# STM32H7B3x register map
File version: 2.2
CPU: CM7 r0p1, little endian, MPU, FPU, 4 interrupt priority bits
Registers are 32-bit, read-write, reset 0x0 unless marked. A register's access mark holds for its fields unless they carry their own. Offsets are from the block's base; [hi:lo] are bit positions; {n}, {i} and the like mark numbered series; 'fields as' and 'values as' point back to an identical list.

## RCC (part 2 of 3) — Reset and clock control
Base 0x58024400
0x44 PLL3FRACR
  [15:3] FRACN3 — fractional part of the multiplication factor for PLL3 VCO Set and reset by software to control the fractional part of the multiplication factor of the VCO. These bits can be written at any time, allowing dynamic fine-tuning of the PLL3 VCO. The software must set correctly these bits to insure that the VCO output frequency is between its valid frequency range, that is: 128 to 560Â MHz if PLL3VCOSEL = 0 150 to 420Â MHz if PLL3VCOSEL = 1 VCO output frequency = Fref3_ck x (DIVN3 + (FRACN3 / 213)), with DIVN3 between 8 and 420 FRACN3 can be between 0 and 213 - 1 The input frequency Fref3_ck must be between 1 and 16 MHz. In order to change the FRACN value on-the-fly even if the PLL is enabled, the application must proceed as follows: Set the bit PLL1FRACEN to 0. Write the new fractional value into FRACN1. Set the bit PLL1FRACEN to 1.
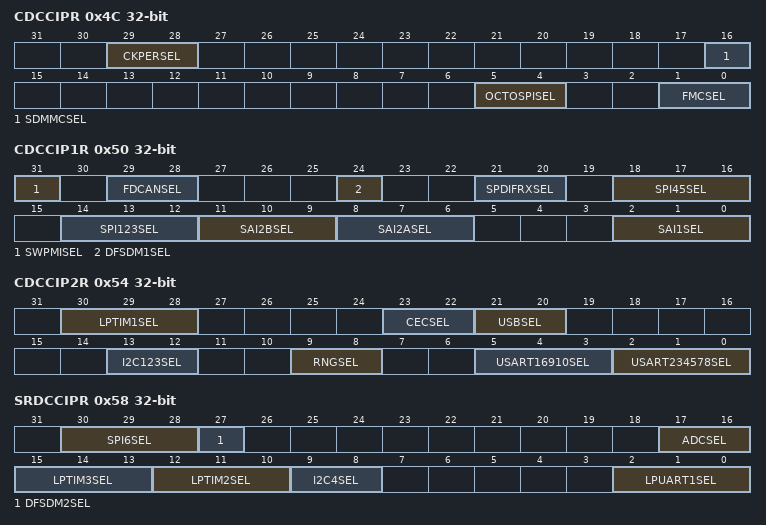
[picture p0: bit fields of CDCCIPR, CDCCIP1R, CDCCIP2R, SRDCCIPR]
0x4C CDCCIPR — RCC CPU domain kernel clock configuration register
  [29:28] CKPERSEL — per_ck clock source selection
    0=HSI (HSI selected as peripheral clock); 1=CSI (CSI selected as peripheral clock); 2=HSE (HSE selected as peripheral clock)
  [16] SDMMCSEL — SDMMC kernel clock source selection
    0=PLL1_Q (pll1_q selected as peripheral clock); 1=PLL2_R (pll2_r selected as peripheral clock)
  [5:4] OCTOSPISEL — OCTOSPI kernel clock source selection
    0=RCC_HCLK3 (rcc_hclk3 selected as peripheral clock); 1=PLL1_Q (pll1_q selected as peripheral clock); 2=PLL2_R (pll2_r selected as peripheral clock); 3=PER (PER selected as peripheral clock)
  [1:0] FMCSEL — FMC kernel clock source selection
    values as OCTOSPISEL
0x50 CDCCIP1R — RCC CPU domain kernel clock configuration register
  [31] SWPMISEL — SWPMI kernel clock source selection Set and reset by software.
    0=PCLK (pclk selected as peripheral clock); 1=HSI_KER (hsi_ker selected as peripheral clock)
  [29:28] FDCANSEL — FDCAN kernel clock source selection Set and reset by software.
    0=HSE (HSE selected as peripheral clock); 1=PLL1_Q (pll1_q selected as peripheral clock); 2=PLL2_Q (pll2_q selected as peripheral clock)
  [24] DFSDM1SEL — DFSDM1 kernel clock Clk source selection Set and reset by software. Note: the DFSDM1 Aclk clock source selection is done by SAI1SEL (see ).
    0=RCC_PCLK2 (rcc_pclk2 selected as peripheral clock); 1=SYS (System clock selected as peripheral clock)
  [21:20] SPDIFRXSEL — SPDIFRX kernel clock source selection
    0=PLL1_Q (pll1_q selected as peripheral clock); 1=PLL2_R (pll2_r selected as peripheral clock); 2=PLL3_R (pll3_r selected as peripheral clock); 3=HSI_KER (hsi_ker selected as peripheral clock)
  [18:16] SPI45SEL — SPI4 and 5 kernel clock source selection Set and reset by software. others: reserved, the kernel clock is disabled
    0=APB (APB clock selected as peripheral clock); 1=PLL2_Q (pll2_q selected as peripheral clock); 2=PLL3_Q (pll3_q selected as peripheral clock); 3=HSI_KER (hsi_ker selected as peripheral clock); 4=CSI_KER (csi_ker selected as peripheral clock); 5=HSE (HSE selected as peripheral clock)
  [14:12] SPI123SEL — SPI/I2S1,2 and 3 kernel clock source selection Set and reset by software. If the selected clock is the external clock and this clock is stopped, it is not be possible to switch to another clock. Refer to for additional information. others: reserved, the kernel clock is disabled Note: I2S_CKIN is an external clock taken from a pin.
    0=PLL1_Q (pll1_q selected as peripheral clock); 1=PLL2_P (pll2_p selected as peripheral clock); 2=PLL3_P (pll3_p selected as peripheral clock); 3=I2S_CKIN (I2S_CKIN selected as peripheral clock); 4=PER (PER selected as peripheral clock)
  [11:9] SAI2BSEL — SAI2 kernel clock B source selection Set and reset by software. If the selected clock is the external clock and this clock is stopped, it is not be possible to switch to another clock. Refer to for additional information. others: reserved, the kernel clock is disabled Note: I2S_CKIN is an external clock taken from a pin. spdifrx_symb_ck is the symbol clock generated by the spdifrx (see ).
    0=PLL1_Q (pll1_q selected as peripheral clock); 1=PLL2_P (pll2_p selected as peripheral clock); 2=PLL3_P (pll3_p selected as peripheral clock); 3=I2S_CKIN (i2s_ckin selected as peripheral clock); 4=PER (PER selected as peripheral clock)
  [8:6] SAI2ASEL — SAI2 kernel clock source A selection Set and reset by software. If the selected clock is the external clock and this clock is stopped, it is not be possible to switch to another clock. Refer to for additional information. others: reserved, the kernel clock is disabled Note: I2S_CKIN is an external clock taken from a pin. spdifrx_symb_ck is the symbol clock generated by the SPDIFRX (see ).
    values as SAI2BSEL
  [2:0] SAI1SEL — SAI1 and DFSDM1 kernel Aclk clock source selection Set and reset by software. If the selected clock is the external clock and this clock is stopped, it isnot be possible to switch to another clock. Refer to for additional information. Note: DFSDM1 clock source selection is done by DFSDM1SEL. others: reserved, the kernel clock is disabled Note: I2S_CKIN is an external clock taken from a pin.
    values as SPI123SEL
0x54 CDCCIP2R — RCC CPU domain kernel clock configuration register
  [30:28] LPTIM1SEL — LPTIM1 kernel clock source selection Set and reset by software. others: reserved, the kernel clock is disabled
    0=RCC_PCLK1 (rcc_pclk1 selected as peripheral clock); 1=PLL2_P (pll2_p selected as peripheral clock); 2=PLL3_R (pll3_r selected as peripheral clock); 3=LSE (LSE selected as peripheral clock); 4=LSI (LSI selected as peripheral clock); 5=PER (PER selected as peripheral clock)
  [23:22] CECSEL — HDMI-CEC kernel clock source selection Set and reset by software.
    0=LSE (LSE selected as peripheral clock); 1=LSI (LSI selected as peripheral clock); 2=CSI_KER (csi_ker selected as peripheral clock)
  [21:20] USBSEL — USBOTG 1 and 2 kernel clock source selection Set and reset by software.
    0=DISABLE (Disable the kernel clock); 1=PLL1_Q (pll1_q selected as peripheral clock); 2=PLL3_Q (pll3_q selected as peripheral clock); 3=HSI48 (HSI48 selected as peripheral clock)
  [13:12] I2C123SEL — I2C1,2,3 kernel clock source selection Set and reset by software.
    0=RCC_PCLK1 (rcc_pclk1 selected as peripheral clock); 1=PLL3_R (pll3_r selected as peripheral clock); 2=HSI_KER (hsi_ker selected as peripheral clock); 3=CSI_KER (csi_ker selected as peripheral clock)
  [9:8] RNGSEL — RNG kernel clock source selection Set and reset by software.
    0=HSI48 (HSI48 selected as peripheral clock); 1=PLL1_Q (pll1_q selected as peripheral clock); 2=LSE (LSE selected as peripheral clock); 3=LSI (LSI selected as peripheral clock)
  [5:3] USART16910SEL — USART1, 6, 9 and 10 kernel clock source selection Set and reset by software. others: reserved, the kernel clock is disabled
    0=RCC_PCLK2 (rcc_pclk2 selected as peripheral clock); 1=PLL2_Q (pll2_q selected as peripheral clock); 2=PLL3_Q (pll3_q selected as peripheral clock); 3=HSI_KER (hsi_ker selected as peripheral clock); 4=CSI_KER (csi_ker selected as peripheral clock); 5=LSE (LSE selected as peripheral clock)
  [2:0] USART234578SEL — USART2/3, UART4,5, 7 and 8 (APB1) kernel clock source selection Set and reset by software. others: reserved, the kernel clock is disabled
    0=RCC_PCLK1 (rcc_pclk1 selected as peripheral clock); 1=PLL2_Q (pll2_q selected as peripheral clock); 2=PLL3_Q (pll3_q selected as peripheral clock); 3=HSI_KER (hsi_ker selected as peripheral clock); 4=CSI_KER (csi_ker selected as peripheral clock); 5=LSE (LSE selected as peripheral clock)
0x58 SRDCCIPR — RCC SmartRun domain kernel clock configuration register
  [30:28] SPI6SEL — SPI6 kernel clock source selection Set and reset by software. others: reserved, the kernel clock is disabled
    0=RCC_PCLK4 (rcc_pclk4 selected as peripheral clock); 1=PLL2_Q (pll2_q selected as peripheral clock); 2=PLL3_Q (pll3_q selected as peripheral clock); 3=HSI_KER (hsi_ker selected as peripheral clock); 4=CSI_KER (csi_ker selected as peripheral clock); 5=HSE (HSE selected as peripheral clock)
  [27] DFSDM2SEL — DFSDM2 kernel Clk clock source selection Set and reset by software. Note: The DFSDM2 Aclk clock source selection is done by SPI6SEL (see and ).
  [17:16] ADCSEL — SAR ADC kernel clock source selection Set and reset by software. others: reserved, the kernel clock is disabled
    0=PLL2_P (pll2_p selected as peripheral clock); 1=PLL3_R (pll3_r selected as peripheral clock); 2=PER (PER selected as peripheral clock)
  [15:13] LPTIM3SEL — LPTIM3 kernel clock source selection Set and reset by software. others: reserved, the kernel clock is disabled
  [12:10] LPTIM2SEL — LPTIM2 kernel clock source selection Set and reset by software. others: reserved, the kernel clock is disabled
    0=RCC_PCLK4 (rcc_pclk4 selected as peripheral clock); 1=PLL2_P (pll2_p selected as peripheral clock); 2=PLL3_R (pll3_r selected as peripheral clock); 3=LSE (LSE selected as peripheral clock); 4=LSI (LSI selected as peripheral clock); 5=PER (PER selected as peripheral clock)
  [9:8] I2C4SEL — I2C4 kernel clock source selection Set and reset by software.
    0=RCC_PCLK4 (rcc_pclk4 selected as peripheral clock); 1=PLL3_R (pll3_r selected as peripheral clock); 2=HSI_KER (hsi_ker selected as peripheral clock); 3=CSI_KER (csi_ker selected as peripheral clock)
  [2:0] LPUART1SEL — LPUART1 kernel clock source selection Set and reset by software. others: reserved, the kernel clock is disabled
    0=RCC_PCLK_D3 (rcc_pclk_d3 selected as peripheral clock); 1=PLL2_Q (pll2_q selected as peripheral clock); 2=PLL3_Q (pll3_q selected as peripheral clock); 3=HSI_KER (hsi_ker selected as peripheral clock); 4=CSI_KER (csi_ker selected as peripheral clock); 5=LSE (LSE selected as peripheral clock)
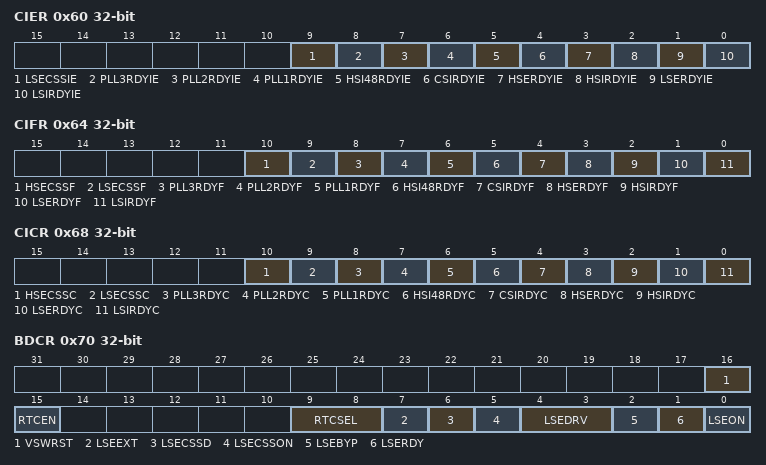
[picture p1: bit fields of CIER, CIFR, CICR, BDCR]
0x60 CIER
  [all] fields
    0=Disabled (Interrupt disabled); 1=Enabled (Interrupt enabled)
  [9] LSECSSIE — LSE clock security system interrupt enable Set and reset by software to enable/disable interrupt caused by the clock security system (CSS) on external 32 kHz oscillator.
  [8] PLL3RDYIE — PLL3 ready interrupt enable Set and reset by software to enable/disable interrupt caused by PLL3 lock.
  [7] PLL2RDYIE — PLL2 ready interrupt enable Set and reset by software to enable/disable interrupt caused by PLL2 lock.
  [6] PLL1RDYIE — PLL1 ready interrupt enable Set and reset by software to enable/disable interrupt caused by PLL1 lock.
  [5] HSI48RDYIE — HSI48 ready interrupt enable Set and reset by software to enable/disable interrupt caused by the HSI48 oscillator stabilization.
  [4] CSIRDYIE — CSI ready interrupt enable Set and reset by software to enable/disable interrupt caused by the CSI oscillator stabilization.
  [3] HSERDYIE — HSE ready interrupt enable Set and reset by software to enable/disable interrupt caused by the HSE oscillator stabilization.
  [2] HSIRDYIE — HSI ready interrupt enable Set and reset by software to enable/disable interrupt caused by the HSI oscillator stabilization.
  [1] LSERDYIE — LSE ready interrupt enable Set and reset by software to enable/disable interrupt caused by the LSE oscillator stabilization.
  [0] LSIRDYIE — LSI ready interrupt enable Set and reset by software to enable/disable interrupt caused by the LSI oscillator stabilization.
0x64 CIFR ro
  [10] HSECSSF — HSE clock security system interrupt flag Reset by software by writing HSECSSC bit. Set by hardware in case of HSE clock failure.
  [9] LSECSSF — LSE clock security system interrupt flag Reset by software by writing LSECSSC bit. Set by hardware when a failure is detected on the external 32 kHz oscillator and LSECSSIE is set.
  [8] PLL3RDYF — PLL3 ready interrupt flag Reset by software by writing PLL3RDYC bit. Set by hardware when the PLL3 locks and PLL3RDYIE is set.
  [7] PLL2RDYF — PLL2 ready interrupt flag Reset by software by writing PLL2RDYC bit. Set by hardware when the PLL2 locks and PLL2RDYIE is set.
  [6] PLL1RDYF — PLL1 ready interrupt flag Reset by software by writing PLL1RDYC bit. Set by hardware when the PLL1 locks and PLL1RDYIE is set.
  [5] HSI48RDYF — HSI48 ready interrupt flag Reset by software by writing HSI48RDYC bit. Set by hardware when the HSI48 clock becomes stable and HSI48RDYIE is set.
  [4] CSIRDYF — CSI ready interrupt flag Reset by software by writing CSIRDYC bit. Set by hardware when the CSI clock becomes stable and CSIRDYIE is set.
  [3] HSERDYF — HSE ready interrupt flag Reset by software by writing HSERDYC bit. Set by hardware when the HSE clock becomes stable and HSERDYIE is set.
  [2] HSIRDYF — HSI ready interrupt flag Reset by software by writing HSIRDYC bit. Set by hardware when the HSI clock becomes stable and HSIRDYIE is set.
  [1] LSERDYF — LSE ready interrupt flag Reset by software by writing LSERDYC bit. Set by hardware when the LSE clock becomes stable and LSERDYIE is set.
  [0] LSIRDYF — LSI ready interrupt flag Reset by software by writing LSIRDYC bit. Set by hardware when the LSI clock becomes stable and LSIRDYIE is set.
0x68 CICR
  [all] fields
    1=Clear interrupt flag
  [10] HSECSSC — HSE clock security system interrupt clear Set by software to clear HSECSSF. Reset by hardware when clear done.
  [9] LSECSSC — LSE clock security system interrupt clear Set by software to clear LSECSSF. Reset by hardware when clear done.
  [8] PLL3RDYC — PLL3 ready interrupt clear Set by software to clear PLL3RDYF. Reset by hardware when clear done.
  [7] PLL2RDYC — PLL2 ready interrupt clear Set by software to clear PLL2RDYF. Reset by hardware when clear done.
  [6] PLL1RDYC — PLL1 ready interrupt clear Set by software to clear PLL1RDYF. Reset by hardware when clear done.
  [5] HSI48RDYC — HSI48 ready interrupt clear Set by software to clear HSI48RDYF. Reset by hardware when clear done.
  [4] CSIRDYC — CSI ready interrupt clear Set by software to clear CSIRDYF. Reset by hardware when clear done.
  [3] HSERDYC — HSE ready interrupt clear Set by software to clear HSERDYF. Reset by hardware when clear done.
  [2] HSIRDYC — HSI ready interrupt clear Set by software to clear HSIRDYF. Reset by hardware when clear done.
  [1] LSERDYC — LSE ready interrupt clear Set by software to clear LSERDYF. Reset by hardware when clear done.
  [0] LSIRDYC — LSI ready interrupt clear Set by software to clear LSIRDYF. Reset by hardware when clear done.
0x70 BDCR access per field — RCC Backup domain control register
  [16] VSWRST rw — VSwitch domain software reset Set and reset by software.
    1=Resets the entire VSW domain
  [15] RTCEN rw — RTC clock enable Set and reset by software.
    0=Disabled (RTC clock disabled); 1=Enabled (RTC clock enabled)
  [9:8] RTCSEL rw-once — RTC clock source selection Set by software to select the clock source for the RTC. These bits can be written only one time (except in case of failure detection on LSE). These bits must be written before LSECSSON is enabled. The VSWRST bit can be used to reset them, then it can be written one time again. If HSE is selected as RTC clock, this clock is lost when the system is in Stop mode or in case of a pin reset (NRST).
    0=NoClock; 1=LSE (LSE oscillator clock used as RTC clock); 2=LSI (LSI oscillator clock used as RTC clock); 3=HSE (HSE oscillator clock divided by a prescaler used as RTC clock)
  [7] LSEEXT rw — low-speed external clock type in Bypass mode Set and reset by software to select the external clock type (analog or digital). The external clock must be enabled with the LSEON bit, to be used by the device. The LSEEXT bit can be written only if the LSE oscillator is disabled.
  [6] LSECSSD ro — LSE clock security system failure detection Set by hardware to indicate when a failure has been detected by the clock security system on the external 32 kHz oscillator.
    on read: 0=No failure detected on 32 kHz oscillator; 1=Failure detected on 32 kHz oscillator
  [5] LSECSSON rw — LSE clock security system enable Set by software to enable the clock security system on 32 kHz oscillator. LSECSSON must be enabled after LSE is enabled (LSEON enabled) and ready (LSERDY set by hardware) and after RTCSEL is selected. Once enabled, this bit cannot be disabled, except after a LSE failure detection (LSECSSD = 1). In that case the software must disable LSECSSON.
    0=SecurityOff (Clock security system on 32 kHz oscillator off); 1=SecurityOn (Clock security system on 32 kHz oscillator on)
  [4:3] LSEDRV rw — LSE oscillator driving capability Set by software to select the driving capability of the LSE oscillator.
    0=Lowest LSE oscillator driving capability; 1=Medium low LSE oscillator driving capability; 2=Medium high LSE oscillator driving capability; 3=Highest LSE oscillator driving capability
  [2] LSEBYP rw — LSE oscillator bypass Set and reset by software to bypass oscillator in debug mode. This bit must not be written when the LSE is enabled (by LSEON) or ready (LSERDY = 1)
    0=NotBypassed (LSE crystal oscillator not bypassed); 1=Bypassed (LSE crystal oscillator bypassed with external clock)
  [1] LSERDY ro — LSE oscillator ready Set and reset by hardware to indicate when the LSE is stable. This bit needs 6 cycles of lse_ck clock to fall down after LSEON has been set to 0.
    on read: 0=NotReady (LSE oscillator not ready); 1=Ready (LSE oscillator ready)
  [0] LSEON rw — LSE oscillator enabled Set and reset by software.
    0=Off (LSE oscillator Off); 1=On (LSE oscillator On)
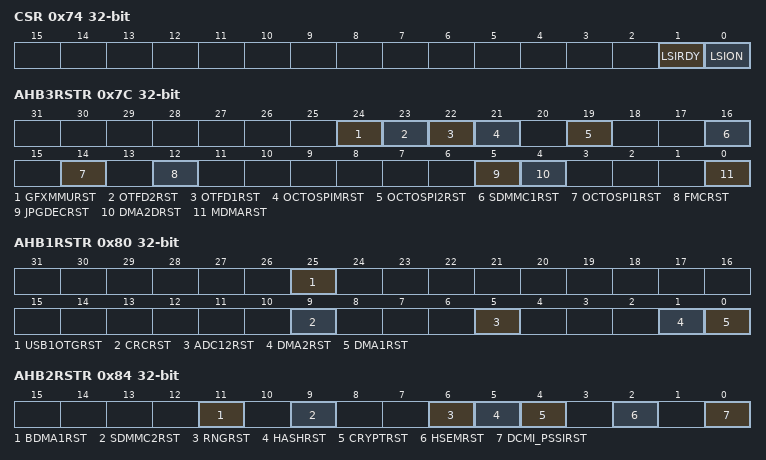
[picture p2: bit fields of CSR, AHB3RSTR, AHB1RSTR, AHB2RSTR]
0x74 CSR access per field — RCC clock control and status register
  [1] LSIRDY ro — LSI oscillator ready Set and reset by hardware to indicate when the low-speed internal RC oscillator is stable. This bit needs 3 cycles of lsi_ck clock to fall down after LSION has been set to 0. This bit can be set even when LSION is not enabled if there is a request for LSI clock by the clock security system on LSE or by the low-speed watchdog or by the RTC.
    on read: 0=NotReady (LSI oscillator not ready); 1=Ready (LSI oscillator ready)
  [0] LSION rw — LSI oscillator enable Set and reset by software.
    0=Off (LSI oscillator Off); 1=On (LSI oscillator On)
0x7C AHB3RSTR
  [all] fields
    1=Reset the selected module
  [24] GFXMMURST — GFXMMU reset Set and reset by software
  [23] OTFD2RST — OTFD2 reset Set and reset by software Take care that resetting the OTFD means loosing the decryption key loaded during secure boot.
  [22] OTFD1RST — OTFD1 reset Set and reset by software Take care that resetting the OTFD means loosing the decryption key loaded during secure boot.
  [21] OCTOSPIMRST — OCTOSPIM reset Set and reset by software
  [19] OCTOSPI2RST — OCTOSPI2 and OCTOSPI2 delay block reset Set and reset by software
  [16] SDMMC1RST — SDMMC1 and SDMMC1 delay blocks reset Set and reset by software.
  [14] OCTOSPI1RST — OCTOSPI1 and OCTOSPI1 delay blocks reset Set and reset by software.
  [12] FMCRST — FMC block reset Set and reset by software.
  [5] JPGDECRST — JPGDEC block reset Set and reset by software.
  [4] DMA2DRST — DMA2D block reset Set and reset by software.
  [0] MDMARST — MDMA block reset Set and reset by software.
0x80 AHB1RSTR
  [all] fields
    1=Reset the selected module
  [25] USB1OTGRST — USB1OTG block reset Set and reset by software.
  [9] CRCRST — CRC block reset Set and reset by software.
  [5] ADC12RST — ADC1 and 2 blocks reset Set and reset by software.
  [1] DMA2RST — DMA2 and DMAMUX2 blocks reset Set and reset by software.
  [0] DMA1RST — DMA1 and DMAMUX1 blocks reset Set and reset by software.
0x84 AHB2RSTR
  [all] fields
    1=Reset the selected module
  [11] BDMA1RST — BDMA1 reset (DFSDM dedicated DMA) Set and reset by software.
  [9] SDMMC2RST — SDMMC2 and SDMMC2 delay blocks reset Set and reset by software.
  [6] RNGRST — random number generator block reset Set and reset by software.
  [5] HASHRST — hash block reset Set and reset by software.
  [4] CRYPTRST — cryptography block reset Set and reset by software.
  [2] HSEMRST — HSEM block reset Set and reset by software.
  [0] DCMI_PSSIRST — digital camera interface block reset (DCMI or PSSI depending which IP is active) Set and reset by software.
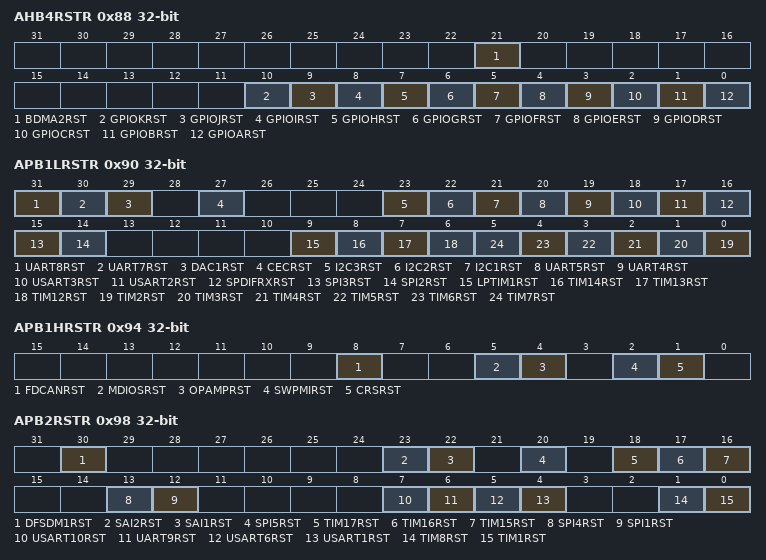
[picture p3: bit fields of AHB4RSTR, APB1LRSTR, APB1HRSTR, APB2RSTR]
0x88 AHB4RSTR
  [all] fields
    1=Reset the selected module
  [21] BDMA2RST — SmartRun domain DMA and DMAMUX blocks reset Set and reset by software.
  [10] GPIOKRST — GPIOK block reset Set and reset by software.
  [9] GPIOJRST — GPIOJ block reset Set and reset by software.
  [8] GPIOIRST — GPIOI block reset Set and reset by software.
  [7] GPIOHRST — GPIOH block reset Set and reset by software.
  [6] GPIOGRST — GPIOG block reset Set and reset by software.
  [5] GPIOFRST — GPIOF block reset Set and reset by software.
  [4] GPIOERST — GPIOE block reset Set and reset by software.
  [3] GPIODRST — GPIOD block reset Set and reset by software.
  [2] GPIOCRST — GPIOC block reset Set and reset by software.
  [1] GPIOBRST — GPIOB block reset Set and reset by software.
  [0] GPIOARST — GPIOA block reset Set and reset by software.
0x8C APB3RSTR
  [3] LTDCRST — LTDC block reset Set and reset by software.
    1=Reset the selected module
0x90 APB1LRSTR
  [all] fields
    1=Reset the selected module
  [31] UART8RST — UART8 block reset Set and reset by software.
  [30] UART7RST — UART7 block reset Set and reset by software.
  [29] DAC1RST — DAC1 (containing two converters) reset Set and reset by software.
  [27] CECRST — HDMI-CEC block reset Set and reset by software.
  [23] I2C3RST — I2C3 block reset Set and reset by software.
  [22] I2C2RST — I2C2 block reset Set and reset by software.
  [21] I2C1RST — I2C1 block reset Set and reset by software.
  [20] UART5RST — UART5 block reset Set and reset by software.
  [19] UART4RST — UART4 block reset Set and reset by software.
  [18] USART3RST — USART3 block reset Set and reset by software.
  [17] USART2RST — USART2 block reset Set and reset by software.
  [16] SPDIFRXRST — SPDIFRX block reset Set and reset by software.
  [15] SPI3RST — SPI3 block reset Set and reset by software.
  [14] SPI2RST — SPI2 block reset Set and reset by software.
  [9] LPTIM1RST — LPTIM1 block reset Set and reset by software.
  [8] TIM14RST — TIM14 block reset Set and reset by software.
  [7] TIM13RST — TIM13 block reset Set and reset by software.
  [6] TIM12RST — TIM12 block reset Set and reset by software.
  [n-2] TIM{n}RST (n=2..7) — TIM{n} block reset Set and reset by software.
0x94 APB1HRSTR
  [all] fields
    1=Reset the selected module
  [8] FDCANRST — FDCAN block reset Set and reset by software.
  [5] MDIOSRST — MDIOS block reset Set and reset by software.
  [4] OPAMPRST — OPAMP block reset Set and reset by software.
  [2] SWPMIRST — SWPMI block reset Set and reset by software.
  [1] CRSRST — clock recovery system reset Set and reset by software.
0x98 APB2RSTR
  [all] fields
    1=Reset the selected module
  [30] DFSDM1RST — DFSDM1 block reset Set and reset by software.
  [23] SAI2RST — SAI2 block reset Set and reset by software.
  [22] SAI1RST — SAI1 block reset Set and reset by software.
  [20] SPI5RST — SPI5 block reset Set and reset by software.
  [18] TIM17RST — TIM17 block reset Set and reset by software.
  [17] TIM16RST — TIM16 block reset Set and reset by software.
  [16] TIM15RST — TIM15 block reset Set and reset by software.
  [13] SPI4RST — SPI4 block reset Set and reset by software.
  [12] SPI1RST — SPI1 block reset Set and reset by software.
  [7] USART10RST — USART10 block reset Set and reset by software.
  [6] UART9RST — UART9 block reset Set and reset by software.
  [5] USART6RST — USART6 block reset Set and reset by software.
  [4] USART1RST — USART1 block reset Set and reset by software.
  [1] TIM8RST — TIM8 block reset Set and reset by software.
  [0] TIM1RST — TIM1 block reset Set and reset by software.
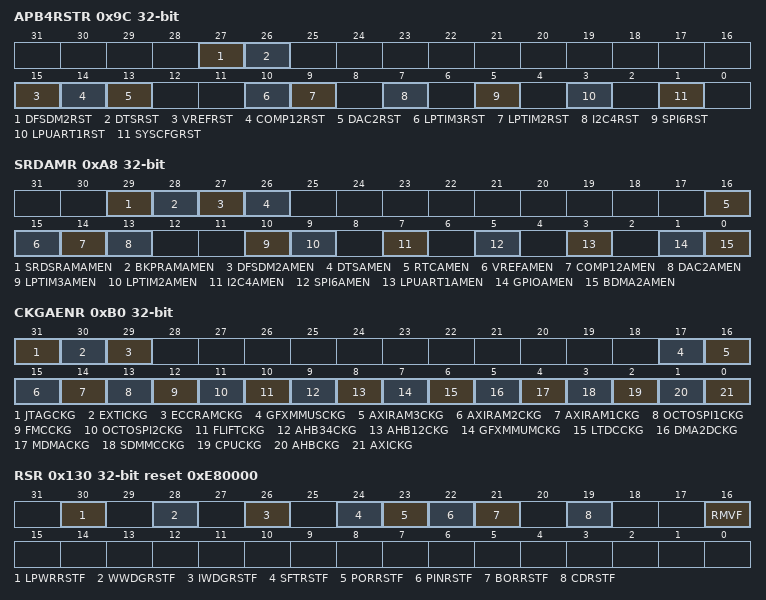
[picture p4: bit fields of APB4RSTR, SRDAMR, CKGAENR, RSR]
0x9C APB4RSTR
  [all] fields
    1=Reset the selected module
  [27] DFSDM2RST — DFSDM2 block reset Set and reset by software.
  [26] DTSRST — Digital temperature sensor block reset Set and reset by software.
  [15] VREFRST — VREF block reset Set and reset by software.
  [14] COMP12RST — COMP1 and 2 blocks reset Set and reset by software.
  [13] DAC2RST — DAC2 (containing one converter) reset Set and reset by software.
  [10] LPTIM3RST — LPTIM3 block reset Set and reset by software.
  [9] LPTIM2RST — LPTIM2 block reset Set and reset by software.
  [7] I2C4RST — I2C4 block reset Set and reset by software.
  [5] SPI6RST — SPI6 block reset Set and reset by software.
  [3] LPUART1RST — LPUART1 block reset Set and reset by software.
  [1] SYSCFGRST — SYSCFG block reset Set and reset by software.
0xA0 GCR — Global Control Register
  [0] WW1RSC — WWDG1 reset scope control
    0=Clear WWDG1 scope control; 1=Set (Set WWDG1 scope control)
0xA8 SRDAMR — RCC SmartRun domain Autonomous mode register
  [all] fields
    0=Disabled (Clock disabled in autonomous mode); 1=Enabled (Clock enabled in autonomous mode)
  [29] SRDSRAMAMEN — SmartRun domain SRAM Autonomous mode enable Set and reset by software. Refer to for additional information.
  [28] BKPRAMAMEN — Backup RAM Autonomous mode enable Set and reset by software. Refer to for additional information.
  [27] DFSDM2AMEN — DFSDM2 Autonomous mode enable Set and reset by software. Refer to for additional information.
  [26] DTSAMEN — Digital temperature sensor Autonomous mode enable Set and reset by software. Refer to for additional information.
  [16] RTCAMEN — RTC Autonomous mode enable Set and reset by software. Refer to for additional information.
  [15] VREFAMEN — VREF Autonomous mode enable Set and reset by software. Refer to for additional information.
  [14] COMP12AMEN — COMP1 and 2 Autonomous mode enable Set and reset by software. Refer to for additional information.
  [13] DAC2AMEN — DAC2 (containing one converter) Autonomous mode enable Set and reset by software. Refer to for additional information.
  [10] LPTIM3AMEN — LPTIM3 Autonomous mode enable Set and reset by software. Refer to for additional information.
  [9] LPTIM2AMEN — LPTIM2 Autonomous mode enable Set and reset by software. Refer to for additional information
  [7] I2C4AMEN — I2C4 Autonomous mode enable Set and reset by software. Refer to for additional information.
  [5] SPI6AMEN — SPI6 Autonomous mode enable Set and reset by software. Refer to for additional information.
  [3] LPUART1AMEN — LPUART1 Autonomous mode enable Set and reset by software. Refer to for additional information.
  [1] GPIOAMEN — GPIO Autonomous mode enable Set and reset by software. Refer to for additional information.
  [0] BDMA2AMEN — SmartRun domain DMA and DMAMUX Autonomous mode enable Set and reset by software. Refer to for additional information.
0xB0 CKGAENR — RCC AXI clocks gating enable register
  [31] JTAGCKG — JTAG automatic clock gating This bit is set and reset by software.
  [30] EXTICKG — EXTI clock gating This bit is set and reset by software.
  [29] ECCRAMCKG — RAM error code correction (ECC) clock gating This bit is set and reset by software.
  [17] GFXMMUSCKG — AXI matrix slave GFXMMU clock gating This bit is set and reset by software.
  [16] AXIRAM3CKG — AXI matrix slave SRAM3 clock gating This bit is set and reset by software.
  [15] AXIRAM2CKG — AXI matrix slave SRAM2 clock gating This bit is set and reset by software.
  [14] AXIRAM1CKG — AXI slave SRAM1 clock gating This bit is set and reset by software.
  [13] OCTOSPI1CKG — AXI slave OCTOSPI1 clock gating This bit is set and reset by software.
  [12] FMCCKG — AXI slave FMC clock gating This bit is set and reset by software.
  [11] OCTOSPI2CKG — AXI slave OCTOSPI2 clock gating This bit is set and reset by software.
  [10] FLIFTCKG — AXI slave Flash interface (FLIFT) clock gating This bit is set and reset by software.
  [9] AHB34CKG — AXI slave AHB34 clock gating This bit is set and reset by software.
  [8] AHB12CKG — AXI slave AHB12 clock gating This bit is set and reset by software.
  [7] GFXMMUMCKG — AXI master GFXMMU clock gating This bit is set and reset by software.
  [6] LTDCCKG — AXI master LTDC clock gating This bit is set and reset by software.
  [5] DMA2DCKG — AXI master DMA2D clock gating This bit is set and reset by software.
  [4] MDMACKG — AXI master MDMA clock gating This bit is set and reset by software.
  [3] SDMMCCKG — AXI master SDMMC clock gating This bit is set and reset by software.
  [2] CPUCKG — AXI master CPU clock gating This bit is set and reset by software.
  [1] AHBCKG — AXI master AHB clock gating This bit is set and reset by software.
  [0] AXICKG — AXI interconnect matrix clock gating This bit is set and reset by software.
0x130 RSR access per field reset 0xE80000 — RCC reset status register
  [30] LPWRRSTF ro — reset due to illegal CD DStop or CD DStop2 or CPU CStop flag Reset by software by writing the RMVF bit. Set by hardware when the CPU domain goes erroneously in DStop or DStop2, or when the CPU goes erroneously in CStop.
    on read: 0=No reset occoured for block; 1=ResetOccourred (Reset occoured for block)
  [28] WWDGRSTF ro — window watchdog reset flag Reset by software by writing the RMVF bit. Set by hardware when a window watchdog reset occurs.
    values as LPWRRSTF
  [26] IWDGRSTF ro — independent watchdog reset flag Reset by software by writing the RMVF bit. Set by hardware when an independent watchdog reset occurs.
    values as LPWRRSTF
  [24] SFTRSTF ro — system reset from CPU reset flag Reset by software by writing the RMVF bit. Set by hardware when the system reset is due to CPU.The CPU can generate a system reset by writing SYSRESETREQ bit of AIRCR register of the core M7.
    values as LPWRRSTF
  [23] PORRSTF ro — POR/PDR reset flag Reset by software by writing the RMVF bit. Set by hardware when a POR/PDR reset occurs.
    values as LPWRRSTF
  [22] PINRSTF ro — pin reset flag (NRST) Reset by software by writing the RMVF bit. Set by hardware when a reset from pin occurs.
    values as LPWRRSTF
  [21] BORRSTF ro — BOR reset flag Reset by software by writing the RMVF bit. Set by hardware when a BOR reset occurs (pwr_bor_rst).
    values as LPWRRSTF
  [19] CDRSTF ro — CPU domain power-switch reset flag Reset by software by writing the RMVF bit. Set by hardware when a the CPU domain exits from DStop or after of power-on reset. Set also when the CPU domain exists DStop2 but only when a pad reset has occurred during DStop2 (PINRST bit also set by hardware)
    values as LPWRRSTF
  [16] RMVF rw — remove reset flag Set and reset by software to reset the value of the reset flags.
    0=NotActive (Not clearing the the reset flags); 1=Clear the reset flags
